AUTOSAR XML (schema 4-0-3)
package /PATAC/MSM/ComponentTypes
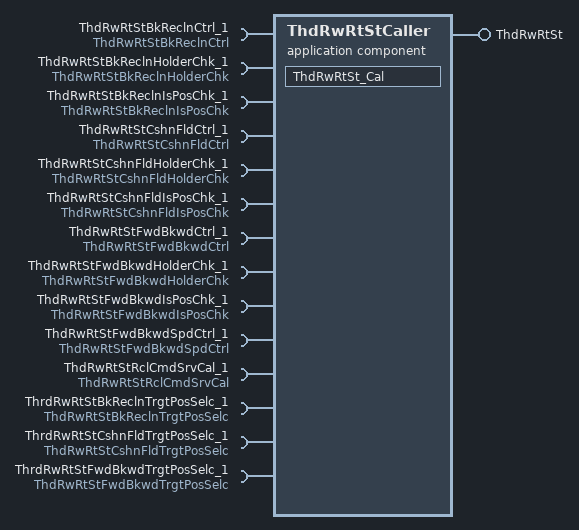
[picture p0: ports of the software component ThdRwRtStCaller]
  application sw component type ThdRwRtStCaller
    provide port ThdRwRtSt: server-com-spec{operation=ThdRwRtSt/Cal, queue-length=1}, provided-interface=ThdRwRtSt
    14 x require port:
      ThdRwRtStBkReclnCtrl_1: client-com-spec=ThdRwRtStBkReclnCtrl/Cal, required-interface=ThdRwRtStBkReclnCtrl
      ThdRwRtStBkReclnHolderChk_1: client-com-spec=ThdRwRtStBkReclnHolderChk/Cal, required-interface=ThdRwRtStBkReclnHolderChk
      ThdRwRtStBkReclnIsPosChk_1: client-com-spec=ThdRwRtStBkReclnIsPosChk/Cal, required-interface=ThdRwRtStBkReclnIsPosChk
      ThdRwRtStCshnFldCtrl_1: client-com-spec=ThdRwRtStCshnFldCtrl/Cal, required-interface=ThdRwRtStCshnFldCtrl
      ThdRwRtStCshnFldHolderChk_1: client-com-spec=ThdRwRtStCshnFldHolderChk/Cal, required-interface=ThdRwRtStCshnFldHolderChk
      ThdRwRtStCshnFldIsPosChk_1: client-com-spec=ThdRwRtStCshnFldIsPosChk/Cal, required-interface=ThdRwRtStCshnFldIsPosChk
      ThdRwRtStFwdBkwdCtrl_1: client-com-spec=ThdRwRtStFwdBkwdCtrl/Cal, required-interface=ThdRwRtStFwdBkwdCtrl
      ThdRwRtStFwdBkwdHolderChk_1: client-com-spec=ThdRwRtStFwdBkwdHolderChk/Cal, required-interface=ThdRwRtStFwdBkwdHolderChk
      ThdRwRtStFwdBkwdIsPosChk_1: client-com-spec=ThdRwRtStFwdBkwdIsPosChk/Cal, required-interface=ThdRwRtStFwdBkwdIsPosChk
      ThdRwRtStFwdBkwdSpdCtrl_1: client-com-spec=ThdRwRtStFwdBkwdSpdCtrl/Cal, required-interface=ThdRwRtStFwdBkwdSpdCtrl
      ThdRwRtStRclCmdSrvCal_1: client-com-spec=ThdRwRtStRclCmdSrvCal/Cal, required-interface=ThdRwRtStRclCmdSrvCal
      ThrdRwRtStBkReclnTrgtPosSelc_1: client-com-spec=ThdRwRtStBkReclnTrgtPosSelc/Cal, required-interface=ThdRwRtStBkReclnTrgtPosSelc
      ThrdRwRtStCshnFldTrgtPosSelc_1: client-com-spec=ThdRwRtStCshnFldTrgtPosSelc/Cal, required-interface=ThdRwRtStCshnFldTrgtPosSelc
      ThrdRwRtStFwdBkwdTrgtPosSelc_1: client-com-spec=ThdRwRtStFwdBkwdTrgtPosSelc/Cal, required-interface=ThdRwRtStFwdBkwdTrgtPosSelc
    behavior ThdRwRtStCaller_InternalBehavior
      operation invoked event OIT_ThdRwRtSt_Cal_ThdRwRtSt_Cal: start-on-event=ThdRwRtSt_Cal, operation=ThdRwRtSt.Cal
      runnable ThdRwRtSt_Cal
        14 x sync call, all with timeout=0:
          SC_ThdRwRtStBkReclnCtrl_1_Cal: operation=ThdRwRtStBkReclnCtrl_1.Cal
          SC_ThdRwRtStBkReclnHolderChk_1_Cal: operation=ThdRwRtStBkReclnHolderChk_1.Cal
          SC_ThdRwRtStBkReclnIsPosChk_1_Cal: operation=ThdRwRtStBkReclnIsPosChk_1.Cal
          SC_ThdRwRtStCshnFldCtrl_1_Cal: operation=ThdRwRtStCshnFldCtrl_1.Cal
          SC_ThdRwRtStCshnFldHolderChk_1_Cal: operation=ThdRwRtStCshnFldHolderChk_1.Cal
          SC_ThdRwRtStCshnFldIsPosChk_1_Cal: operation=ThdRwRtStCshnFldIsPosChk_1.Cal
          SC_ThdRwRtStFwdBkwdCtrl_1_Cal: operation=ThdRwRtStFwdBkwdCtrl_1.Cal
          SC_ThdRwRtStFwdBkwdHolderChk_1_Cal: operation=ThdRwRtStFwdBkwdHolderChk_1.Cal
          SC_ThdRwRtStFwdBkwdIsPosChk_1_Cal: operation=ThdRwRtStFwdBkwdIsPosChk_1.Cal
          SC_ThdRwRtStFwdBkwdSpdCtrl_1_Cal: operation=ThdRwRtStFwdBkwdSpdCtrl_1.Cal
          SC_ThdRwRtStRclCmdSrvCal_1_Cal: operation=ThdRwRtStRclCmdSrvCal_1.Cal
          SC_ThrdRwRtStBkReclnTrgtPosSelc_1_Cal: operation=ThrdRwRtStBkReclnTrgtPosSelc_1.Cal
          SC_ThrdRwRtStCshnFldTrgtPosSelc_1_Cal: operation=ThrdRwRtStCshnFldTrgtPosSelc_1.Cal
          SC_ThrdRwRtStFwdBkwdTrgtPosSelc_1_Cal: operation=ThrdRwRtStFwdBkwdTrgtPosSelc_1.Cal
  swc implementation ThdRwRtStCaller_Implementation: behavior=ThdRwRtStCaller_InternalBehavior
    code-descriptors:
      code Default: artifact-descriptors=autosar-engineering-object={short-label=Default, category=SWSRC}
package /PATAC/MSM/ModeAdjust/PortInterface
  15 x client server interface:
    ThdRwRtSt
      operation Cal
    ThdRwRtStBkReclnCtrl
      operation Cal
    ThdRwRtStBkReclnHolderChk
      operation Cal
    ThdRwRtStBkReclnIsPosChk
      operation Cal
    ThdRwRtStBkReclnTrgtPosSelc
      operation Cal
    ThdRwRtStCshnFldCtrl
      operation Cal
    ThdRwRtStCshnFldHolderChk
      operation Cal
    ThdRwRtStCshnFldIsPosChk
      operation Cal
    ThdRwRtStCshnFldTrgtPosSelc
      operation Cal
    ThdRwRtStFwdBkwdCtrl
      operation Cal
    ThdRwRtStFwdBkwdHolderChk
      operation Cal
    ThdRwRtStFwdBkwdIsPosChk
      operation Cal
    ThdRwRtStFwdBkwdSpdCtrl
      operation Cal
    ThdRwRtStFwdBkwdTrgtPosSelc
      operation Cal
    ThdRwRtStRclCmdSrvCal
      operation Cal
